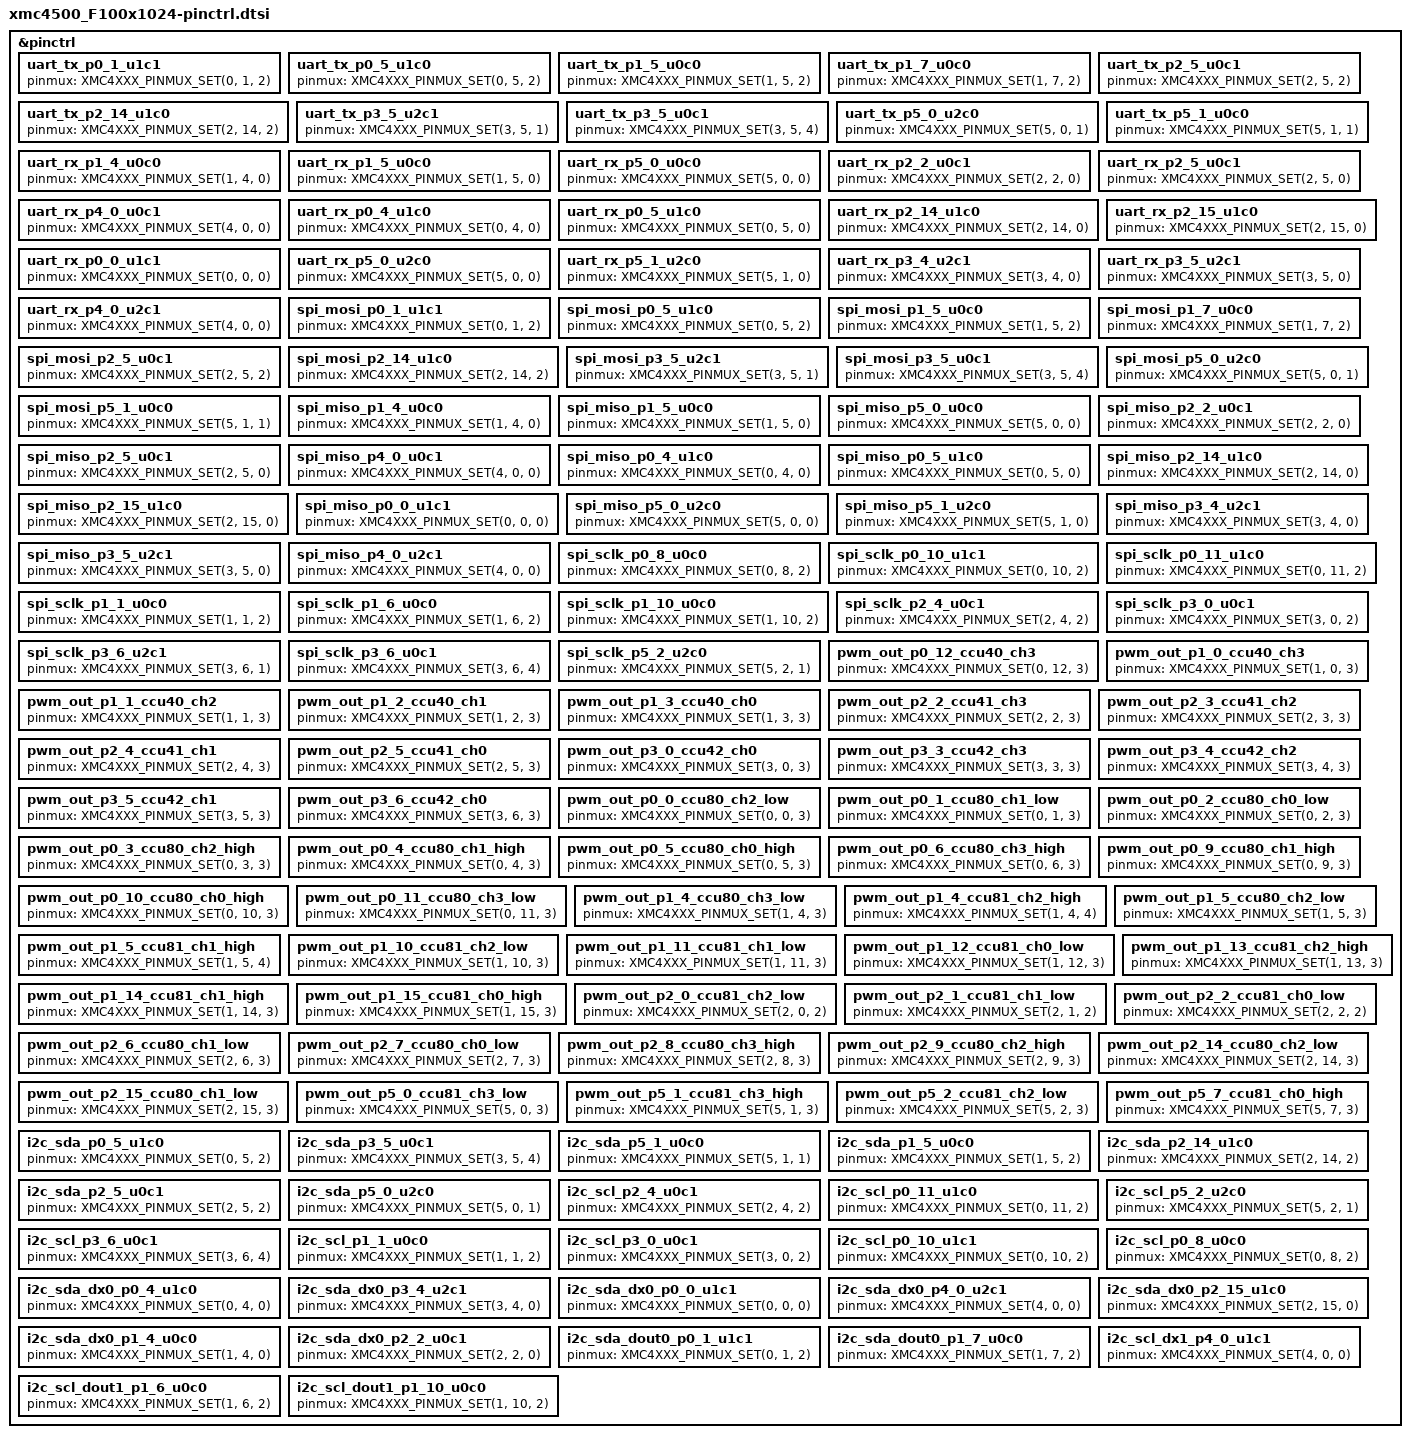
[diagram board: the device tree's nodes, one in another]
/*
 * Copyright (c) 2022 Schlumberger
 * SPDX-License-Identifier: Apache-2.0
 */

#include <infineon/xmc4xxx.dtsi>
#include <zephyr/dt-bindings/pinctrl/xmc4xxx-pinctrl.h>

&pinctrl {
	/omit-if-no-ref/ uart_tx_p0_1_u1c1: uart_tx_p0_1_u1c1 {
		pinmux = <XMC4XXX_PINMUX_SET(0, 1, 2)>;
	};
	/omit-if-no-ref/ uart_tx_p0_5_u1c0: uart_tx_p0_5_u1c0 {
		pinmux = <XMC4XXX_PINMUX_SET(0, 5, 2)>;
	};
	/omit-if-no-ref/ uart_tx_p1_5_u0c0: uart_tx_p1_5_u0c0 {
		pinmux = <XMC4XXX_PINMUX_SET(1, 5, 2)>;
	};
	/omit-if-no-ref/ uart_tx_p1_7_u0c0: uart_tx_p1_7_u0c0 {
		pinmux = <XMC4XXX_PINMUX_SET(1, 7, 2)>;
	};
	/omit-if-no-ref/ uart_tx_p2_5_u0c1: uart_tx_p2_5_u0c1 {
		pinmux = <XMC4XXX_PINMUX_SET(2, 5, 2)>;
	};
	/omit-if-no-ref/ uart_tx_p2_14_u1c0: uart_tx_p2_14_u1c0 {
		pinmux = <XMC4XXX_PINMUX_SET(2, 14, 2)>;
	};
	/omit-if-no-ref/ uart_tx_p3_5_u2c1: uart_tx_p3_5_u2c1 {
		pinmux = <XMC4XXX_PINMUX_SET(3, 5, 1)>;
	};
	/omit-if-no-ref/ uart_tx_p3_5_u0c1: uart_tx_p3_5_u0c1 {
		pinmux = <XMC4XXX_PINMUX_SET(3, 5, 4)>;
	};
	/omit-if-no-ref/ uart_tx_p5_0_u2c0: uart_tx_p5_0_u2c0 {
		pinmux = <XMC4XXX_PINMUX_SET(5, 0, 1)>;
	};
	/omit-if-no-ref/ uart_tx_p5_1_u0c0: uart_tx_p5_1_u0c0 {
		pinmux = <XMC4XXX_PINMUX_SET(5, 1, 1)>;
	};

	/omit-if-no-ref/ uart_rx_p1_4_u0c0: uart_rx_p1_4_u0c0 {
		pinmux = <XMC4XXX_PINMUX_SET(1, 4, 0)>;	/* USIC input src = DX0B */
	};
	/omit-if-no-ref/ uart_rx_p1_5_u0c0: uart_rx_p1_5_u0c0 {
		pinmux = <XMC4XXX_PINMUX_SET(1, 5, 0)>;	/* USIC input src = DX0A */
	};
	/omit-if-no-ref/ uart_rx_p5_0_u0c0: uart_rx_p5_0_u0c0 {
		pinmux = <XMC4XXX_PINMUX_SET(5, 0, 0)>;	/* USIC input src = DX0D */
	};
	/omit-if-no-ref/ uart_rx_p2_2_u0c1: uart_rx_p2_2_u0c1 {
		pinmux = <XMC4XXX_PINMUX_SET(2, 2, 0)>;	/* USIC input src = DX0A */
	};
	/omit-if-no-ref/ uart_rx_p2_5_u0c1: uart_rx_p2_5_u0c1 {
		pinmux = <XMC4XXX_PINMUX_SET(2, 5, 0)>;	/* USIC input src = DX0B */
	};
	/omit-if-no-ref/ uart_rx_p4_0_u0c1: uart_rx_p4_0_u0c1 {
		pinmux = <XMC4XXX_PINMUX_SET(4, 0, 0)>;	/* USIC input src = DX0E */
	};
	/omit-if-no-ref/ uart_rx_p0_4_u1c0: uart_rx_p0_4_u1c0 {
		pinmux = <XMC4XXX_PINMUX_SET(0, 4, 0)>;	/* USIC input src = DX0A */
	};
	/omit-if-no-ref/ uart_rx_p0_5_u1c0: uart_rx_p0_5_u1c0 {
		pinmux = <XMC4XXX_PINMUX_SET(0, 5, 0)>;	/* USIC input src = DX0B */
	};
	/omit-if-no-ref/ uart_rx_p2_14_u1c0: uart_rx_p2_14_u1c0 {
		pinmux = <XMC4XXX_PINMUX_SET(2, 14, 0)>;	/* USIC input src = DX0D */
	};
	/omit-if-no-ref/ uart_rx_p2_15_u1c0: uart_rx_p2_15_u1c0 {
		pinmux = <XMC4XXX_PINMUX_SET(2, 15, 0)>;	/* USIC input src = DX0C */
	};
	/omit-if-no-ref/ uart_rx_p0_0_u1c1: uart_rx_p0_0_u1c1 {
		pinmux = <XMC4XXX_PINMUX_SET(0, 0, 0)>;	/* USIC input src = DX0D */
	};
	/omit-if-no-ref/ uart_rx_p5_0_u2c0: uart_rx_p5_0_u2c0 {
		pinmux = <XMC4XXX_PINMUX_SET(5, 0, 0)>;	/* USIC input src = DX0B */
	};
	/omit-if-no-ref/ uart_rx_p5_1_u2c0: uart_rx_p5_1_u2c0 {
		pinmux = <XMC4XXX_PINMUX_SET(5, 1, 0)>;	/* USIC input src = DX0A */
	};
	/omit-if-no-ref/ uart_rx_p3_4_u2c1: uart_rx_p3_4_u2c1 {
		pinmux = <XMC4XXX_PINMUX_SET(3, 4, 0)>;	/* USIC input src = DX0B */
	};
	/omit-if-no-ref/ uart_rx_p3_5_u2c1: uart_rx_p3_5_u2c1 {
		pinmux = <XMC4XXX_PINMUX_SET(3, 5, 0)>;	/* USIC input src = DX0A */
	};
	/omit-if-no-ref/ uart_rx_p4_0_u2c1: uart_rx_p4_0_u2c1 {
		pinmux = <XMC4XXX_PINMUX_SET(4, 0, 0)>;	/* USIC input src = DX0C */
	};

	/omit-if-no-ref/ spi_mosi_p0_1_u1c1: spi_mosi_p0_1_u1c1 {
		pinmux = <XMC4XXX_PINMUX_SET(0, 1, 2)>;
	};
	/omit-if-no-ref/ spi_mosi_p0_5_u1c0: spi_mosi_p0_5_u1c0 {
		pinmux = <XMC4XXX_PINMUX_SET(0, 5, 2)>;
	};
	/omit-if-no-ref/ spi_mosi_p1_5_u0c0: spi_mosi_p1_5_u0c0 {
		pinmux = <XMC4XXX_PINMUX_SET(1, 5, 2)>;
	};
	/omit-if-no-ref/ spi_mosi_p1_7_u0c0: spi_mosi_p1_7_u0c0 {
		pinmux = <XMC4XXX_PINMUX_SET(1, 7, 2)>;
	};
	/omit-if-no-ref/ spi_mosi_p2_5_u0c1: spi_mosi_p2_5_u0c1 {
		pinmux = <XMC4XXX_PINMUX_SET(2, 5, 2)>;
	};
	/omit-if-no-ref/ spi_mosi_p2_14_u1c0: spi_mosi_p2_14_u1c0 {
		pinmux = <XMC4XXX_PINMUX_SET(2, 14, 2)>;
	};
	/omit-if-no-ref/ spi_mosi_p3_5_u2c1: spi_mosi_p3_5_u2c1 {
		pinmux = <XMC4XXX_PINMUX_SET(3, 5, 1)>;
	};
	/omit-if-no-ref/ spi_mosi_p3_5_u0c1: spi_mosi_p3_5_u0c1 {
		pinmux = <XMC4XXX_PINMUX_SET(3, 5, 4)>;
	};
	/omit-if-no-ref/ spi_mosi_p5_0_u2c0: spi_mosi_p5_0_u2c0 {
		pinmux = <XMC4XXX_PINMUX_SET(5, 0, 1)>;
	};
	/omit-if-no-ref/ spi_mosi_p5_1_u0c0: spi_mosi_p5_1_u0c0 {
		pinmux = <XMC4XXX_PINMUX_SET(5, 1, 1)>;
	};

	/omit-if-no-ref/ spi_miso_p1_4_u0c0: spi_miso_p1_4_u0c0 {
		pinmux = <XMC4XXX_PINMUX_SET(1, 4, 0)>;	/* USIC input src = DX0B */
	};
	/omit-if-no-ref/ spi_miso_p1_5_u0c0: spi_miso_p1_5_u0c0 {
		pinmux = <XMC4XXX_PINMUX_SET(1, 5, 0)>;	/* USIC input src = DX0A */
	};
	/omit-if-no-ref/ spi_miso_p5_0_u0c0: spi_miso_p5_0_u0c0 {
		pinmux = <XMC4XXX_PINMUX_SET(5, 0, 0)>;	/* USIC input src = DX0D */
	};
	/omit-if-no-ref/ spi_miso_p2_2_u0c1: spi_miso_p2_2_u0c1 {
		pinmux = <XMC4XXX_PINMUX_SET(2, 2, 0)>;	/* USIC input src = DX0A */
	};
	/omit-if-no-ref/ spi_miso_p2_5_u0c1: spi_miso_p2_5_u0c1 {
		pinmux = <XMC4XXX_PINMUX_SET(2, 5, 0)>;	/* USIC input src = DX0B */
	};
	/omit-if-no-ref/ spi_miso_p4_0_u0c1: spi_miso_p4_0_u0c1 {
		pinmux = <XMC4XXX_PINMUX_SET(4, 0, 0)>;	/* USIC input src = DX0E */
	};
	/omit-if-no-ref/ spi_miso_p0_4_u1c0: spi_miso_p0_4_u1c0 {
		pinmux = <XMC4XXX_PINMUX_SET(0, 4, 0)>;	/* USIC input src = DX0A */
	};
	/omit-if-no-ref/ spi_miso_p0_5_u1c0: spi_miso_p0_5_u1c0 {
		pinmux = <XMC4XXX_PINMUX_SET(0, 5, 0)>;	/* USIC input src = DX0B */
	};
	/omit-if-no-ref/ spi_miso_p2_14_u1c0: spi_miso_p2_14_u1c0 {
		pinmux = <XMC4XXX_PINMUX_SET(2, 14, 0)>;	/* USIC input src = DX0D */
	};
	/omit-if-no-ref/ spi_miso_p2_15_u1c0: spi_miso_p2_15_u1c0 {
		pinmux = <XMC4XXX_PINMUX_SET(2, 15, 0)>;	/* USIC input src = DX0C */
	};
	/omit-if-no-ref/ spi_miso_p0_0_u1c1: spi_miso_p0_0_u1c1 {
		pinmux = <XMC4XXX_PINMUX_SET(0, 0, 0)>;	/* USIC input src = DX0D */
	};
	/omit-if-no-ref/ spi_miso_p5_0_u2c0: spi_miso_p5_0_u2c0 {
		pinmux = <XMC4XXX_PINMUX_SET(5, 0, 0)>;	/* USIC input src = DX0B */
	};
	/omit-if-no-ref/ spi_miso_p5_1_u2c0: spi_miso_p5_1_u2c0 {
		pinmux = <XMC4XXX_PINMUX_SET(5, 1, 0)>;	/* USIC input src = DX0A */
	};
	/omit-if-no-ref/ spi_miso_p3_4_u2c1: spi_miso_p3_4_u2c1 {
		pinmux = <XMC4XXX_PINMUX_SET(3, 4, 0)>;	/* USIC input src = DX0B */
	};
	/omit-if-no-ref/ spi_miso_p3_5_u2c1: spi_miso_p3_5_u2c1 {
		pinmux = <XMC4XXX_PINMUX_SET(3, 5, 0)>;	/* USIC input src = DX0A */
	};
	/omit-if-no-ref/ spi_miso_p4_0_u2c1: spi_miso_p4_0_u2c1 {
		pinmux = <XMC4XXX_PINMUX_SET(4, 0, 0)>;	/* USIC input src = DX0C */
	};
	/omit-if-no-ref/ spi_sclk_p0_8_u0c0: spi_sclk_p0_8_u0c0 {
		pinmux = <XMC4XXX_PINMUX_SET(0, 8, 2)>;
	};
	/omit-if-no-ref/ spi_sclk_p0_10_u1c1: spi_sclk_p0_10_u1c1 {
		pinmux = <XMC4XXX_PINMUX_SET(0, 10, 2)>;
	};
	/omit-if-no-ref/ spi_sclk_p0_11_u1c0: spi_sclk_p0_11_u1c0 {
		pinmux = <XMC4XXX_PINMUX_SET(0, 11, 2)>;
	};
	/omit-if-no-ref/ spi_sclk_p1_1_u0c0: spi_sclk_p1_1_u0c0 {
		pinmux = <XMC4XXX_PINMUX_SET(1, 1, 2)>;
	};
	/omit-if-no-ref/ spi_sclk_p1_6_u0c0: spi_sclk_p1_6_u0c0 {
		pinmux = <XMC4XXX_PINMUX_SET(1, 6, 2)>;
	};
	/omit-if-no-ref/ spi_sclk_p1_10_u0c0: spi_sclk_p1_10_u0c0 {
		pinmux = <XMC4XXX_PINMUX_SET(1, 10, 2)>;
	};
	/omit-if-no-ref/ spi_sclk_p2_4_u0c1: spi_sclk_p2_4_u0c1 {
		pinmux = <XMC4XXX_PINMUX_SET(2, 4, 2)>;
	};
	/omit-if-no-ref/ spi_sclk_p3_0_u0c1: spi_sclk_p3_0_u0c1 {
		pinmux = <XMC4XXX_PINMUX_SET(3, 0, 2)>;
	};
	/omit-if-no-ref/ spi_sclk_p3_6_u2c1: spi_sclk_p3_6_u2c1 {
		pinmux = <XMC4XXX_PINMUX_SET(3, 6, 1)>;
	};
	/omit-if-no-ref/ spi_sclk_p3_6_u0c1: spi_sclk_p3_6_u0c1 {
		pinmux = <XMC4XXX_PINMUX_SET(3, 6, 4)>;
	};
	/omit-if-no-ref/ spi_sclk_p5_2_u2c0: spi_sclk_p5_2_u2c0 {
		pinmux = <XMC4XXX_PINMUX_SET(5, 2, 1)>;
	};

	/omit-if-no-ref/ pwm_out_p0_12_ccu40_ch3: pwm_out_p0_12_ccu40_ch3 {
		pinmux = <XMC4XXX_PINMUX_SET(0, 12, 3)>;
	};
	/omit-if-no-ref/ pwm_out_p1_0_ccu40_ch3: pwm_out_p1_0_ccu40_ch3 {
		pinmux = <XMC4XXX_PINMUX_SET(1, 0, 3)>;
	};
	/omit-if-no-ref/ pwm_out_p1_1_ccu40_ch2: pwm_out_p1_1_ccu40_ch2 {
		pinmux = <XMC4XXX_PINMUX_SET(1, 1, 3)>;
	};
	/omit-if-no-ref/ pwm_out_p1_2_ccu40_ch1: pwm_out_p1_2_ccu40_ch1 {
		pinmux = <XMC4XXX_PINMUX_SET(1, 2, 3)>;
	};
	/omit-if-no-ref/ pwm_out_p1_3_ccu40_ch0: pwm_out_p1_3_ccu40_ch0 {
		pinmux = <XMC4XXX_PINMUX_SET(1, 3, 3)>;
	};
	/omit-if-no-ref/ pwm_out_p2_2_ccu41_ch3: pwm_out_p2_2_ccu41_ch3 {
		pinmux = <XMC4XXX_PINMUX_SET(2, 2, 3)>;
	};
	/omit-if-no-ref/ pwm_out_p2_3_ccu41_ch2: pwm_out_p2_3_ccu41_ch2 {
		pinmux = <XMC4XXX_PINMUX_SET(2, 3, 3)>;
	};
	/omit-if-no-ref/ pwm_out_p2_4_ccu41_ch1: pwm_out_p2_4_ccu41_ch1 {
		pinmux = <XMC4XXX_PINMUX_SET(2, 4, 3)>;
	};
	/omit-if-no-ref/ pwm_out_p2_5_ccu41_ch0: pwm_out_p2_5_ccu41_ch0 {
		pinmux = <XMC4XXX_PINMUX_SET(2, 5, 3)>;
	};
	/omit-if-no-ref/ pwm_out_p3_0_ccu42_ch0: pwm_out_p3_0_ccu42_ch0 {
		pinmux = <XMC4XXX_PINMUX_SET(3, 0, 3)>;
	};
	/omit-if-no-ref/ pwm_out_p3_3_ccu42_ch3: pwm_out_p3_3_ccu42_ch3 {
		pinmux = <XMC4XXX_PINMUX_SET(3, 3, 3)>;
	};
	/omit-if-no-ref/ pwm_out_p3_4_ccu42_ch2: pwm_out_p3_4_ccu42_ch2 {
		pinmux = <XMC4XXX_PINMUX_SET(3, 4, 3)>;
	};
	/omit-if-no-ref/ pwm_out_p3_5_ccu42_ch1: pwm_out_p3_5_ccu42_ch1 {
		pinmux = <XMC4XXX_PINMUX_SET(3, 5, 3)>;
	};
	/omit-if-no-ref/ pwm_out_p3_6_ccu42_ch0: pwm_out_p3_6_ccu42_ch0 {
		pinmux = <XMC4XXX_PINMUX_SET(3, 6, 3)>;
	};

	/omit-if-no-ref/ pwm_out_p0_0_ccu80_ch2_low: pwm_out_p0_0_ccu80_ch2_low {
		pinmux = <XMC4XXX_PINMUX_SET(0, 0, 3)>;
	};
	/omit-if-no-ref/ pwm_out_p0_1_ccu80_ch1_low: pwm_out_p0_1_ccu80_ch1_low {
		pinmux = <XMC4XXX_PINMUX_SET(0, 1, 3)>;
	};
	/omit-if-no-ref/ pwm_out_p0_2_ccu80_ch0_low: pwm_out_p0_2_ccu80_ch0_low {
		pinmux = <XMC4XXX_PINMUX_SET(0, 2, 3)>;
	};
	/omit-if-no-ref/ pwm_out_p0_3_ccu80_ch2_high: pwm_out_p0_3_ccu80_ch2_high {
		pinmux = <XMC4XXX_PINMUX_SET(0, 3, 3)>;
	};
	/omit-if-no-ref/ pwm_out_p0_4_ccu80_ch1_high: pwm_out_p0_4_ccu80_ch1_high {
		pinmux = <XMC4XXX_PINMUX_SET(0, 4, 3)>;
	};
	/omit-if-no-ref/ pwm_out_p0_5_ccu80_ch0_high: pwm_out_p0_5_ccu80_ch0_high {
		pinmux = <XMC4XXX_PINMUX_SET(0, 5, 3)>;
	};
	/omit-if-no-ref/ pwm_out_p0_6_ccu80_ch3_high: pwm_out_p0_6_ccu80_ch3_high {
		pinmux = <XMC4XXX_PINMUX_SET(0, 6, 3)>;
	};
	/omit-if-no-ref/ pwm_out_p0_9_ccu80_ch1_high: pwm_out_p0_9_ccu80_ch1_high {
		pinmux = <XMC4XXX_PINMUX_SET(0, 9, 3)>;
	};
	/omit-if-no-ref/ pwm_out_p0_10_ccu80_ch0_high: pwm_out_p0_10_ccu80_ch0_high {
		pinmux = <XMC4XXX_PINMUX_SET(0, 10, 3)>;
	};
	/omit-if-no-ref/ pwm_out_p0_11_ccu80_ch3_low: pwm_out_p0_11_ccu80_ch3_low {
		pinmux = <XMC4XXX_PINMUX_SET(0, 11, 3)>;
	};
	/omit-if-no-ref/ pwm_out_p1_4_ccu80_ch3_low: pwm_out_p1_4_ccu80_ch3_low {
		pinmux = <XMC4XXX_PINMUX_SET(1, 4, 3)>;
	};
	/omit-if-no-ref/ pwm_out_p1_4_ccu81_ch2_high: pwm_out_p1_4_ccu81_ch2_high {
		pinmux = <XMC4XXX_PINMUX_SET(1, 4, 4)>;
	};
	/omit-if-no-ref/ pwm_out_p1_5_ccu80_ch2_low: pwm_out_p1_5_ccu80_ch2_low {
		pinmux = <XMC4XXX_PINMUX_SET(1, 5, 3)>;
	};
	/omit-if-no-ref/ pwm_out_p1_5_ccu81_ch1_high: pwm_out_p1_5_ccu81_ch1_high {
		pinmux = <XMC4XXX_PINMUX_SET(1, 5, 4)>;
	};
	/omit-if-no-ref/ pwm_out_p1_10_ccu81_ch2_low: pwm_out_p1_10_ccu81_ch2_low {
		pinmux = <XMC4XXX_PINMUX_SET(1, 10, 3)>;
	};
	/omit-if-no-ref/ pwm_out_p1_11_ccu81_ch1_low: pwm_out_p1_11_ccu81_ch1_low {
		pinmux = <XMC4XXX_PINMUX_SET(1, 11, 3)>;
	};
	/omit-if-no-ref/ pwm_out_p1_12_ccu81_ch0_low: pwm_out_p1_12_ccu81_ch0_low {
		pinmux = <XMC4XXX_PINMUX_SET(1, 12, 3)>;
	};
	/omit-if-no-ref/ pwm_out_p1_13_ccu81_ch2_high: pwm_out_p1_13_ccu81_ch2_high {
		pinmux = <XMC4XXX_PINMUX_SET(1, 13, 3)>;
	};
	/omit-if-no-ref/ pwm_out_p1_14_ccu81_ch1_high: pwm_out_p1_14_ccu81_ch1_high {
		pinmux = <XMC4XXX_PINMUX_SET(1, 14, 3)>;
	};
	/omit-if-no-ref/ pwm_out_p1_15_ccu81_ch0_high: pwm_out_p1_15_ccu81_ch0_high {
		pinmux = <XMC4XXX_PINMUX_SET(1, 15, 3)>;
	};
	/omit-if-no-ref/ pwm_out_p2_0_ccu81_ch2_low: pwm_out_p2_0_ccu81_ch2_low {
		pinmux = <XMC4XXX_PINMUX_SET(2, 0, 2)>;
	};
	/omit-if-no-ref/ pwm_out_p2_1_ccu81_ch1_low: pwm_out_p2_1_ccu81_ch1_low {
		pinmux = <XMC4XXX_PINMUX_SET(2, 1, 2)>;
	};
	/omit-if-no-ref/ pwm_out_p2_2_ccu81_ch0_low: pwm_out_p2_2_ccu81_ch0_low {
		pinmux = <XMC4XXX_PINMUX_SET(2, 2, 2)>;
	};
	/omit-if-no-ref/ pwm_out_p2_6_ccu80_ch1_low: pwm_out_p2_6_ccu80_ch1_low {
		pinmux = <XMC4XXX_PINMUX_SET(2, 6, 3)>;
	};
	/omit-if-no-ref/ pwm_out_p2_7_ccu80_ch0_low: pwm_out_p2_7_ccu80_ch0_low {
		pinmux = <XMC4XXX_PINMUX_SET(2, 7, 3)>;
	};
	/omit-if-no-ref/ pwm_out_p2_8_ccu80_ch3_high: pwm_out_p2_8_ccu80_ch3_high {
		pinmux = <XMC4XXX_PINMUX_SET(2, 8, 3)>;
	};
	/omit-if-no-ref/ pwm_out_p2_9_ccu80_ch2_high: pwm_out_p2_9_ccu80_ch2_high {
		pinmux = <XMC4XXX_PINMUX_SET(2, 9, 3)>;
	};
	/omit-if-no-ref/ pwm_out_p2_14_ccu80_ch2_low: pwm_out_p2_14_ccu80_ch2_low {
		pinmux = <XMC4XXX_PINMUX_SET(2, 14, 3)>;
	};
	/omit-if-no-ref/ pwm_out_p2_15_ccu80_ch1_low: pwm_out_p2_15_ccu80_ch1_low {
		pinmux = <XMC4XXX_PINMUX_SET(2, 15, 3)>;
	};
	/omit-if-no-ref/ pwm_out_p5_0_ccu81_ch3_low: pwm_out_p5_0_ccu81_ch3_low {
		pinmux = <XMC4XXX_PINMUX_SET(5, 0, 3)>;
	};
	/omit-if-no-ref/ pwm_out_p5_1_ccu81_ch3_high: pwm_out_p5_1_ccu81_ch3_high {
		pinmux = <XMC4XXX_PINMUX_SET(5, 1, 3)>;
	};
	/omit-if-no-ref/ pwm_out_p5_2_ccu81_ch2_low: pwm_out_p5_2_ccu81_ch2_low {
		pinmux = <XMC4XXX_PINMUX_SET(5, 2, 3)>;
	};
	/omit-if-no-ref/ pwm_out_p5_7_ccu81_ch0_high: pwm_out_p5_7_ccu81_ch0_high {
		pinmux = <XMC4XXX_PINMUX_SET(5, 7, 3)>;
	};
	/omit-if-no-ref/ i2c_sda_p0_5_u1c0: i2c_sda_p0_5_u1c0 {
		pinmux = <XMC4XXX_PINMUX_SET(0, 5, 2)>; /* USIC sda-src = DX0B */
	};
	/omit-if-no-ref/ i2c_sda_p3_5_u0c1: i2c_sda_p3_5_u0c1 {
		pinmux = <XMC4XXX_PINMUX_SET(3, 5, 4)>; /* USIC sda-src = DX0A */
	};
	/omit-if-no-ref/ i2c_sda_p5_1_u0c0: i2c_sda_p5_1_u0c0 {
		pinmux = <XMC4XXX_PINMUX_SET(5, 1, 1)>; /* USIC sda-src = DX0A */
	};
	/omit-if-no-ref/ i2c_sda_p1_5_u0c0: i2c_sda_p1_5_u0c0 {
		pinmux = <XMC4XXX_PINMUX_SET(1, 5, 2)>; /* USIC sda-src = DX0A */
	};
	/omit-if-no-ref/ i2c_sda_p2_14_u1c0: i2c_sda_p2_14_u1c0 {
		pinmux = <XMC4XXX_PINMUX_SET(2, 14, 2)>; /* USIC sda-src = DX0D */
	};
	/omit-if-no-ref/ i2c_sda_p2_5_u0c1: i2c_sda_p2_5_u0c1 {
		pinmux = <XMC4XXX_PINMUX_SET(2, 5, 2)>; /* USIC sda-src = DX0B */
	};
	/omit-if-no-ref/ i2c_sda_p5_0_u2c0: i2c_sda_p5_0_u2c0 {
		pinmux = <XMC4XXX_PINMUX_SET(5, 0, 1)>; /* USIC sda-src = DX0B */
	};

	/omit-if-no-ref/ i2c_scl_p2_4_u0c1: i2c_scl_p2_4_u0c1 {
		pinmux = <XMC4XXX_PINMUX_SET(2, 4, 2)>; /* USIC scl-src = DX1A */
	};
	/omit-if-no-ref/ i2c_scl_p0_11_u1c0: i2c_scl_p0_11_u1c0 {
		pinmux = <XMC4XXX_PINMUX_SET(0, 11, 2)>; /* USIC scl-src = DX1A */
	};
	/omit-if-no-ref/ i2c_scl_p5_2_u2c0: i2c_scl_p5_2_u2c0 {
		pinmux = <XMC4XXX_PINMUX_SET(5, 2, 1)>; /* USIC scl-src = DX1A */
	};
	/omit-if-no-ref/ i2c_scl_p3_6_u0c1: i2c_scl_p3_6_u0c1 {
		pinmux = <XMC4XXX_PINMUX_SET(3, 6, 4)>; /* USIC scl-src = DX1B */
	};
	/omit-if-no-ref/ i2c_scl_p1_1_u0c0: i2c_scl_p1_1_u0c0 {
		pinmux = <XMC4XXX_PINMUX_SET(1, 1, 2)>; /* USIC scl-src = DX1A */
	};
	/omit-if-no-ref/ i2c_scl_p3_0_u0c1: i2c_scl_p3_0_u0c1 {
		pinmux = <XMC4XXX_PINMUX_SET(3, 0, 2)>; /* USIC scl-src = DX1B */
	};
	/omit-if-no-ref/ i2c_scl_p0_10_u1c1: i2c_scl_p0_10_u1c1 {
		pinmux = <XMC4XXX_PINMUX_SET(0, 10, 2)>; /* USIC scl-src = DX1A */
	};
	/omit-if-no-ref/ i2c_scl_p0_8_u0c0: i2c_scl_p0_8_u0c0 {
		pinmux = <XMC4XXX_PINMUX_SET(0, 8, 2)>; /* USIC scl-src = DX1B */
	};

	/omit-if-no-ref/ i2c_sda_dx0_p0_4_u1c0: i2c_sda_dx0_p0_4_u1c0 {
		pinmux = <XMC4XXX_PINMUX_SET(0, 4, 0)>; /* USIC sda-src = DX0A */
	};
	/omit-if-no-ref/ i2c_sda_dx0_p3_4_u2c1: i2c_sda_dx0_p3_4_u2c1 {
		pinmux = <XMC4XXX_PINMUX_SET(3, 4, 0)>; /* USIC sda-src = DX0B */
	};
	/omit-if-no-ref/ i2c_sda_dx0_p0_0_u1c1: i2c_sda_dx0_p0_0_u1c1 {
		pinmux = <XMC4XXX_PINMUX_SET(0, 0, 0)>; /* USIC sda-src = DX0D */
	};
	/omit-if-no-ref/ i2c_sda_dx0_p4_0_u2c1: i2c_sda_dx0_p4_0_u2c1 {
		pinmux = <XMC4XXX_PINMUX_SET(4, 0, 0)>; /* USIC sda-src = DX0C */
	};
	/omit-if-no-ref/ i2c_sda_dx0_p2_15_u1c0: i2c_sda_dx0_p2_15_u1c0 {
		pinmux = <XMC4XXX_PINMUX_SET(2, 15, 0)>; /* USIC sda-src = DX0C */
	};
	/omit-if-no-ref/ i2c_sda_dx0_p1_4_u0c0: i2c_sda_dx0_p1_4_u0c0 {
		pinmux = <XMC4XXX_PINMUX_SET(1, 4, 0)>; /* USIC sda-src = DX0B */
	};
	/omit-if-no-ref/ i2c_sda_dx0_p2_2_u0c1: i2c_sda_dx0_p2_2_u0c1 {
		pinmux = <XMC4XXX_PINMUX_SET(2, 2, 0)>; /* USIC sda-src = DX0A */
	};
	/omit-if-no-ref/ i2c_sda_dout0_p0_1_u1c1: i2c_sda_dout0_p0_1_u1c1 {
		pinmux = <XMC4XXX_PINMUX_SET(0, 1, 2)>;
	};
	/omit-if-no-ref/ i2c_sda_dout0_p1_7_u0c0: i2c_sda_dout0_p1_7_u0c0 {
		pinmux = <XMC4XXX_PINMUX_SET(1, 7, 2)>;
	};
	/omit-if-no-ref/ i2c_scl_dx1_p4_0_u1c1: i2c_scl_dx1_p4_0_u1c1 {
		pinmux = <XMC4XXX_PINMUX_SET(4, 0, 0)>; /* USIC scl-src = DX1C */
	};
	/omit-if-no-ref/ i2c_scl_dout1_p1_6_u0c0: i2c_scl_dout1_p1_6_u0c0 {
		pinmux = <XMC4XXX_PINMUX_SET(1, 6, 2)>;
	};
	/omit-if-no-ref/ i2c_scl_dout1_p1_10_u0c0: i2c_scl_dout1_p1_10_u0c0 {
		pinmux = <XMC4XXX_PINMUX_SET(1, 10, 2)>;
	};
};
